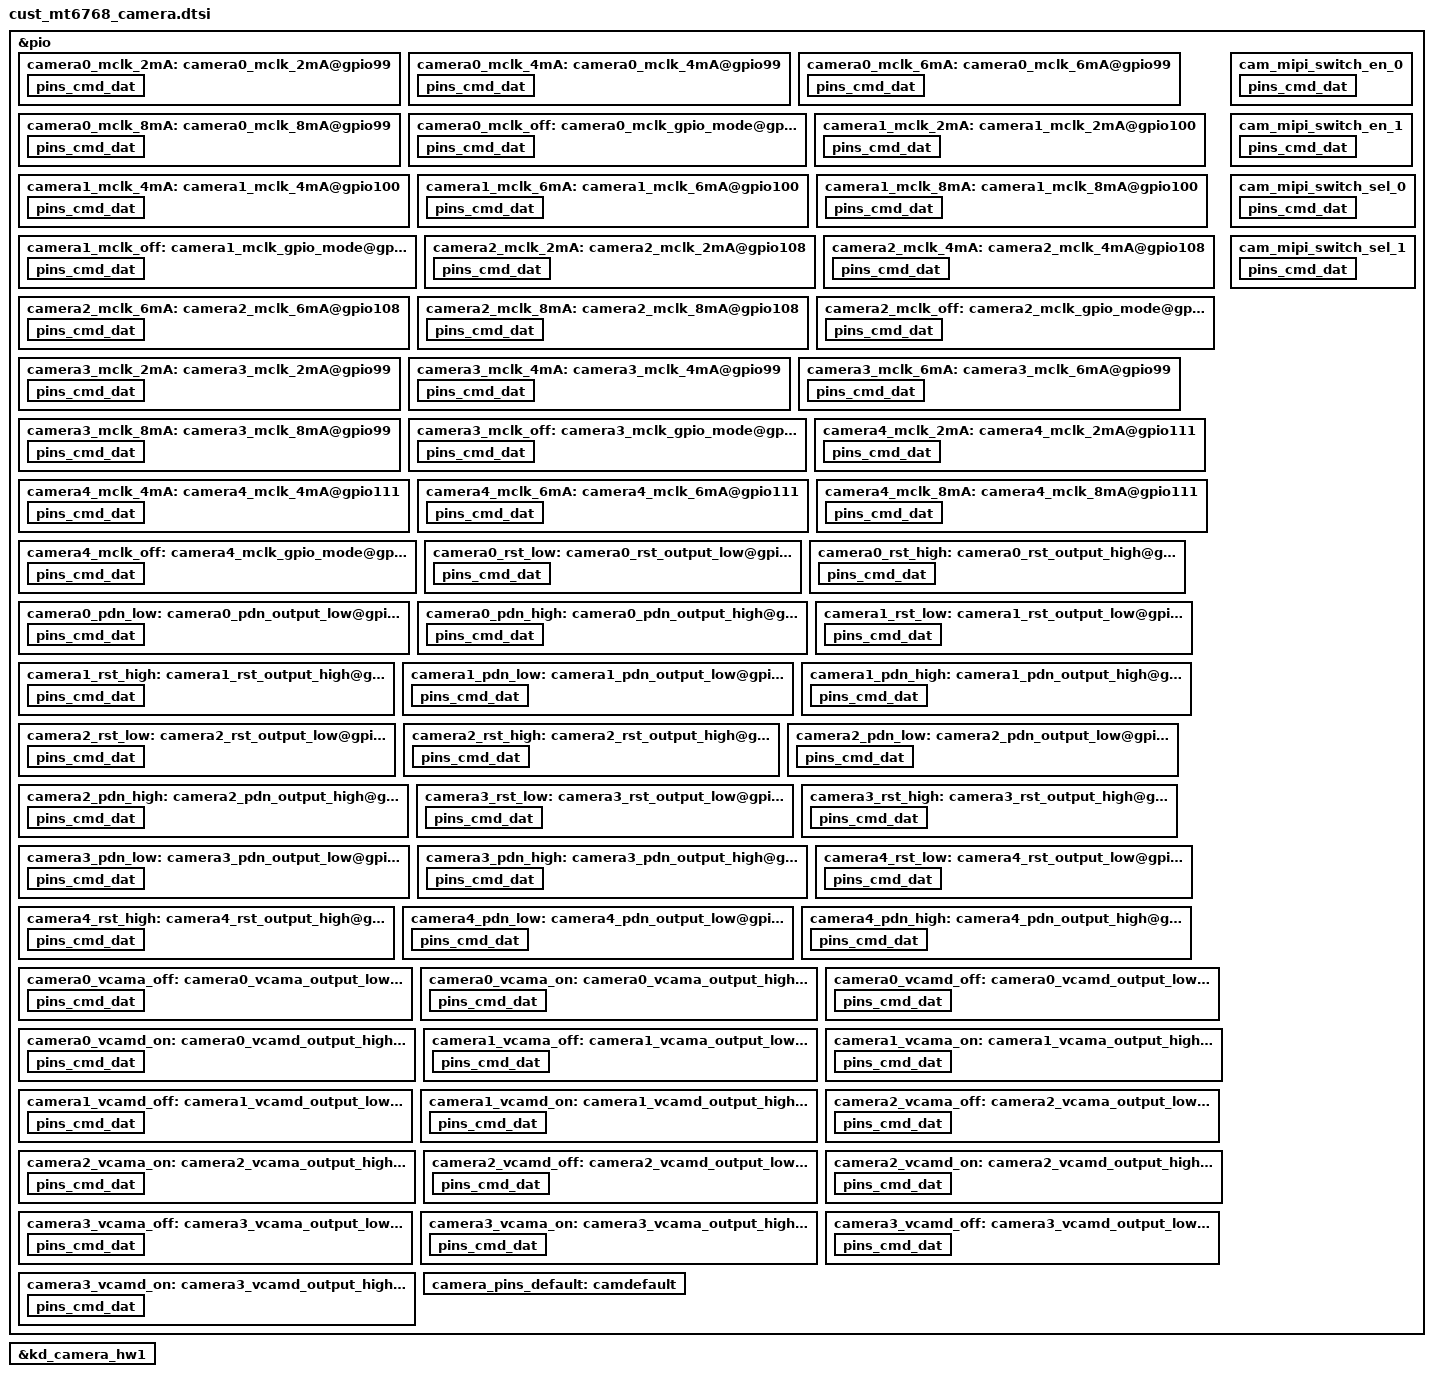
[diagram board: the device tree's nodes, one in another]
/*
 * Copyright (c) 2019 MediaTek Inc.
 *
 * This program is free software; you can redistribute it and/or modify
 * it under the terms of the GNU General Public License version 2 as
 * published by the Free Software Foundation.
 *
 * This program is distributed in the hope that it will be useful,
 * but WITHOUT ANY WARRANTY; without even the implied warranty of
 * MERCHANTABILITY or FITNESS FOR A PARTICULAR PURPOSE.  See the
 * GNU General Public License for more details.
 */
/* CAMERA GPIO standardization */
/*prize add by zhuzhengjiang for 6601 camera 20200902 start*/
&pio {
	camera0_mclk_2mA: camera0_mclk_2mA@gpio99 {
		pins_cmd_dat {
			pinmux = <PINMUX_GPIO99__FUNC_CMMCLK0>;
			drive-strength = <MTK_DRIVE_2mA>;
		};
	};
	camera0_mclk_4mA: camera0_mclk_4mA@gpio99 {
		pins_cmd_dat {
			pinmux = <PINMUX_GPIO99__FUNC_CMMCLK0>;
			drive-strength = <MTK_DRIVE_4mA>;
		};
	};
	camera0_mclk_6mA: camera0_mclk_6mA@gpio99 {
		pins_cmd_dat {
			pinmux = <PINMUX_GPIO99__FUNC_CMMCLK0>;
			drive-strength = <MTK_DRIVE_6mA>;
		};
	};
	camera0_mclk_8mA: camera0_mclk_8mA@gpio99 {
		pins_cmd_dat {
			pinmux = <PINMUX_GPIO99__FUNC_CMMCLK0>;
			drive-strength = <7>;
		};
	};
	camera0_mclk_off: camera0_mclk_gpio_mode@gpio99 {
		pins_cmd_dat {
			pinmux = <PINMUX_GPIO99__FUNC_GPIO99>;
			drive-strength = <MTK_DRIVE_4mA>;
		};
	};
	camera1_mclk_2mA: camera1_mclk_2mA@gpio100 {
		pins_cmd_dat {
			pinmux = <PINMUX_GPIO100__FUNC_CMMCLK1>;
			drive-strength = <MTK_DRIVE_2mA>;
		};
	};
	camera1_mclk_4mA: camera1_mclk_4mA@gpio100 {
		pins_cmd_dat {
			pinmux = <PINMUX_GPIO100__FUNC_CMMCLK1>;
			drive-strength = <MTK_DRIVE_4mA>;
		};
	};
	camera1_mclk_6mA: camera1_mclk_6mA@gpio100 {
		pins_cmd_dat {
			pinmux = <PINMUX_GPIO100__FUNC_CMMCLK1>;
			drive-strength = <MTK_DRIVE_6mA>;
		};
	};
	camera1_mclk_8mA: camera1_mclk_8mA@gpio100 {
		pins_cmd_dat {
			pinmux = <PINMUX_GPIO100__FUNC_CMMCLK1>;
			drive-strength = <7>;
		};
	};
	camera1_mclk_off: camera1_mclk_gpio_mode@gpio100 {
		pins_cmd_dat {
			pinmux = <PINMUX_GPIO100__FUNC_GPIO100>;
			drive-strength = <MTK_DRIVE_4mA>;
		};
	};
	camera2_mclk_2mA: camera2_mclk_2mA@gpio108 {
		pins_cmd_dat {
			pinmux = <PINMUX_GPIO108__FUNC_CMMCLK2>;
			drive-strength = <MTK_DRIVE_2mA>;
		};
	};
	camera2_mclk_4mA: camera2_mclk_4mA@gpio108 {
		pins_cmd_dat {
			pinmux = <PINMUX_GPIO108__FUNC_CMMCLK2>;
			drive-strength = <MTK_DRIVE_4mA>;
		};
	};
	camera2_mclk_6mA: camera2_mclk_6mA@gpio108 {
		pins_cmd_dat {
			pinmux = <PINMUX_GPIO108__FUNC_CMMCLK2>;
			drive-strength = <MTK_DRIVE_6mA>;
		};
	};
	camera2_mclk_8mA: camera2_mclk_8mA@gpio108 {
		pins_cmd_dat {
			pinmux = <PINMUX_GPIO108__FUNC_CMMCLK2>;
			drive-strength = <7>;
		};
	};
	camera2_mclk_off: camera2_mclk_gpio_mode@gpio108 {
		pins_cmd_dat {
			pinmux = <PINMUX_GPIO108__FUNC_GPIO108>;
			drive-strength = <MTK_DRIVE_4mA>;
		};
	};
	//prize add by zhuzhengjiang for mclk start
	camera3_mclk_2mA: camera3_mclk_2mA@gpio99 {
		pins_cmd_dat {
			pinmux = <PINMUX_GPIO99__FUNC_CMMCLK0>;
			drive-strength = <MTK_DRIVE_2mA>;
		};
	};
	camera3_mclk_4mA: camera3_mclk_4mA@gpio99 {
		pins_cmd_dat {
			pinmux = <PINMUX_GPIO99__FUNC_CMMCLK0>;
			drive-strength = <MTK_DRIVE_4mA>;
		};
	};
	camera3_mclk_6mA: camera3_mclk_6mA@gpio99 {
		pins_cmd_dat {
			pinmux = <PINMUX_GPIO99__FUNC_CMMCLK0>;
			drive-strength = <MTK_DRIVE_6mA>;
		};
	};
	camera3_mclk_8mA: camera3_mclk_8mA@gpio99 {
		pins_cmd_dat {
			pinmux = <PINMUX_GPIO99__FUNC_CMMCLK0>;
			drive-strength = <7>;
		};
	};
	camera3_mclk_off: camera3_mclk_gpio_mode@gpio99 {
		pins_cmd_dat {
			pinmux = <PINMUX_GPIO99__FUNC_GPIO99>;
			drive-strength = <MTK_DRIVE_4mA>;
		};
	};
	
	camera4_mclk_2mA: camera4_mclk_2mA@gpio111 {
		pins_cmd_dat {
			pinmux = <PINMUX_GPIO111__FUNC_CMMCLK3>;
			drive-strength = <MTK_DRIVE_2mA>;
		};
	};
	camera4_mclk_4mA: camera4_mclk_4mA@gpio111 {
		pins_cmd_dat {
			pinmux = <PINMUX_GPIO111__FUNC_CMMCLK3>;
			drive-strength = <MTK_DRIVE_4mA>;
		};
	};
	camera4_mclk_6mA: camera4_mclk_6mA@gpio111 {
		pins_cmd_dat {
			pinmux = <PINMUX_GPIO111__FUNC_CMMCLK3>;
			drive-strength = <MTK_DRIVE_6mA>;
		};
	};
	camera4_mclk_8mA: camera4_mclk_8mA@gpio111 {
		pins_cmd_dat {
			pinmux = <PINMUX_GPIO111__FUNC_CMMCLK3>;
			drive-strength = <7>;
		};
	};
	camera4_mclk_off: camera4_mclk_gpio_mode@gpio111 {
		pins_cmd_dat {
			pinmux = <PINMUX_GPIO111__FUNC_GPIO111>;
			drive-strength = <MTK_DRIVE_4mA>;
		};
	};
	//prize add by zhuzhengjiang for mclk end
	camera0_rst_low: camera0_rst_output_low@gpio109 {
		pins_cmd_dat {
			pinmux = <PINMUX_GPIO109__FUNC_GPIO109>;
			output-low;
		};
	};
	camera0_rst_high: camera0_rst_output_high@gpio109 {
		pins_cmd_dat {
			pinmux = <PINMUX_GPIO109__FUNC_GPIO109>;
			output-high;
		};
	};
	camera0_pdn_low: camera0_pdn_output_low@gpio107 {
		pins_cmd_dat {
			pinmux = <PINMUX_GPIO107__FUNC_GPIO107>;
			output-low;
		};
	};
	camera0_pdn_high: camera0_pdn_output_high@gpio107 {
		pins_cmd_dat {
			pinmux = <PINMUX_GPIO107__FUNC_GPIO107>;
			output-high;
		};
	};
	camera1_rst_low: camera1_rst_output_low@gpio102 {
		pins_cmd_dat {
			pinmux = <PINMUX_GPIO102__FUNC_GPIO102>;
			output-low;
		};
	};
	camera1_rst_high: camera1_rst_output_high@gpio102 {
		pins_cmd_dat {
			pinmux = <PINMUX_GPIO102__FUNC_GPIO102>;
			output-high;
		};
	};
	camera1_pdn_low: camera1_pdn_output_low@gpio98 {
		pins_cmd_dat {
			pinmux = <PINMUX_GPIO98__FUNC_GPIO98>;
			slew-rate = <1>;
			output-low;
		};
	};
	camera1_pdn_high: camera1_pdn_output_high@gpio98 {
		pins_cmd_dat {
			pinmux = <PINMUX_GPIO98__FUNC_GPIO98>;
			output-high;
		};
	};
	camera2_rst_low: camera2_rst_output_low@gpio101 {
		pins_cmd_dat {
			pinmux = <PINMUX_GPIO101__FUNC_GPIO101>;
			output-low;
		};
	};
	camera2_rst_high: camera2_rst_output_high@gpio101 {
		pins_cmd_dat {
			pinmux = <PINMUX_GPIO101__FUNC_GPIO101>;
			output-high;
		};
	};
	camera2_pdn_low: camera2_pdn_output_low@gpio97 {
		pins_cmd_dat {
			pinmux = <PINMUX_GPIO97__FUNC_GPIO97>;
			output-low;
		};
	};
	camera2_pdn_high: camera2_pdn_output_high@gpio97 {
		pins_cmd_dat {
			pinmux = <PINMUX_GPIO97__FUNC_GPIO97>;
			output-high;
		};
	};
	//prize add by zhuzhengjiang for cam3/cam4 rst/pdn start
	camera3_rst_low: camera3_rst_output_low@gpio16 {
		pins_cmd_dat {
			pinmux = <PINMUX_GPIO16__FUNC_GPIO16>;
			output-low;
		};
	};
	camera3_rst_high: camera3_rst_output_high@gpio16 {
		pins_cmd_dat {
			pinmux = <PINMUX_GPIO16__FUNC_GPIO16>;
			output-high;
		};
	};
	camera3_pdn_low: camera3_pdn_output_low@gpio14 {
		pins_cmd_dat {
			pinmux = <PINMUX_GPIO14__FUNC_GPIO14>;
			output-low;
		};
	};
	camera3_pdn_high: camera3_pdn_output_high@gpio14 {
		pins_cmd_dat {
			pinmux = <PINMUX_GPIO14__FUNC_GPIO14>;
			output-high;
		};
	};
	
	camera4_rst_low: camera4_rst_output_low@gpio92 {
		pins_cmd_dat {
			pinmux = <PINMUX_GPIO92__FUNC_GPIO92>;
			output-low;
		};
	};
	camera4_rst_high: camera4_rst_output_high@gpio92 {
		pins_cmd_dat {
			pinmux = <PINMUX_GPIO92__FUNC_GPIO92>;
			output-high;
		};
	};
	camera4_pdn_low: camera4_pdn_output_low@gpio110 {
		pins_cmd_dat {
			pinmux = <PINMUX_GPIO110__FUNC_GPIO110>;
			output-low;
		};
	};
	camera4_pdn_high: camera4_pdn_output_high@gpio110 {
		pins_cmd_dat {
			pinmux = <PINMUX_GPIO110__FUNC_GPIO110>;
			output-high;
		};
	};
	//prize add by zhuzhengjiang for cam3/cam4 rst/pdn end
    /* prize liaoxingen add camera dts 20200901 start  */
	camera0_vcama_off: camera0_vcama_output_low@gpio79 {
		pins_cmd_dat {
			pinmux = <PINMUX_GPIO79__FUNC_GPIO79>;
			output-low;
		};
	};
	camera0_vcama_on: camera0_vcama_output_high@gpio79 {
		pins_cmd_dat {
			pinmux = <PINMUX_GPIO79__FUNC_GPIO79>;
			output-high;
		};
	};
    /* prize liaoxingen add camera dts 20200901 end  */

	camera0_vcamd_off: camera0_vcamd_output_low@gpio80 {
		pins_cmd_dat {
			pinmux = <PINMUX_GPIO80__FUNC_GPIO80>;
			output-low;
		};
	};
	camera0_vcamd_on: camera0_vcamd_output_high@gpio80 {
		pins_cmd_dat {
			pinmux = <PINMUX_GPIO80__FUNC_GPIO80>;
			output-high;
		};
	};
    /* prize liaoxingen add camera dts 20200901 start  */
	camera1_vcama_off: camera1_vcama_output_low@gpio54 {
		pins_cmd_dat {
			pinmux = <PINMUX_GPIO54__FUNC_GPIO54>;
			output-low;
		};
	};
	camera1_vcama_on: camera1_vcama_output_high@gpio54 {
		pins_cmd_dat {
			pinmux = <PINMUX_GPIO54__FUNC_GPIO54>;
			output-high;
		};
	};
    /* prize liaoxingen add camera dts 20200901 end  */
	camera1_vcamd_off: camera1_vcamd_output_low@gpio31 {
		pins_cmd_dat {
			pinmux = <PINMUX_GPIO31__FUNC_GPIO31>;
			output-low;
		};
	};
	camera1_vcamd_on: camera1_vcamd_output_high@gpio31 {
		pins_cmd_dat {
			pinmux = <PINMUX_GPIO31__FUNC_GPIO31>;
			output-high;
		};
	};
	camera2_vcama_off: camera2_vcama_output_low@gpio150 {
		pins_cmd_dat {
			pinmux = <PINMUX_GPIO150__FUNC_GPIO150>;
			output-low;
		};
	};
	camera2_vcama_on: camera2_vcama_output_high@gpio150 {
		pins_cmd_dat {
			pinmux = <PINMUX_GPIO150__FUNC_GPIO150>;
			output-high;
		};
	};
	camera2_vcamd_off: camera2_vcamd_output_low@gpio160 {
		pins_cmd_dat {
			pinmux = <PINMUX_GPIO160__FUNC_GPIO160>;
			output-low;
		};
	};
	camera2_vcamd_on: camera2_vcamd_output_high@gpio160 {
		pins_cmd_dat {
			pinmux = <PINMUX_GPIO160__FUNC_GPIO160>;
			output-high;
		};
	};
	camera3_vcama_off: camera3_vcama_output_low@gpio24 {
		pins_cmd_dat {
			pinmux = <PINMUX_GPIO24__FUNC_GPIO24>;
			output-low;
		};
	};
	camera3_vcama_on: camera3_vcama_output_high@gpio24 {
		pins_cmd_dat {
			pinmux = <PINMUX_GPIO24__FUNC_GPIO24>;
			output-high;
		};
	};
	camera3_vcamd_off: camera3_vcamd_output_low@gpio21 {
		pins_cmd_dat {
			pinmux = <PINMUX_GPIO21__FUNC_GPIO21>;
			output-low;
		};
	};
	camera3_vcamd_on: camera3_vcamd_output_high@gpio21 {
		pins_cmd_dat {
			pinmux = <PINMUX_GPIO21__FUNC_GPIO21>;
			output-high;
		};
	};

	cam_mipi_switch_en_0: cam_mipi_switch_en_0 {
		pins_cmd_dat {
			pinmux = <PINMUX_GPIO13__FUNC_GPIO13>;
			slew-rate = <1>;
			output-low;
		};
	};
	cam_mipi_switch_en_1: cam_mipi_switch_en_1 {
		pins_cmd_dat {
			pinmux = <PINMUX_GPIO13__FUNC_GPIO13>;
			slew-rate = <1>;
			output-high;
		};
	};
	cam_mipi_switch_sel_0: cam_mipi_switch_sel_0 {
		pins_cmd_dat {
			pinmux = <PINMUX_GPIO15__FUNC_GPIO15>;
			slew-rate = <1>;
			output-low;
		};
	};
	cam_mipi_switch_sel_1: cam_mipi_switch_sel_1 {
		pins_cmd_dat {
			pinmux = <PINMUX_GPIO15__FUNC_GPIO15>;
			slew-rate = <1>;
			output-high;
		};
	};

	camera_pins_default: camdefault {
	};

};

&kd_camera_hw1 {
	pinctrl-names = "default",
			"cam0_rst0", "cam0_rst1",
			"cam0_pnd0", "cam0_pnd1",
			"cam1_rst0", "cam1_rst1",
			"cam1_pnd0", "cam1_pnd1",
			"cam2_rst0", "cam2_rst1",
			"cam2_pnd0", "cam2_pnd1",
			"cam0_vcamd_on",
			"cam0_vcamd_off",
			"cam1_vcamd_on",
			"cam1_vcamd_off",
			"cam0_vcama_on",
			"cam0_vcama_off",
			"cam1_vcama_on",
			"cam1_vcama_off",
			"cam0_mclk_off",
			"cam0_mclk_2mA", "cam0_mclk_4mA",
			"cam0_mclk_6mA", "cam0_mclk_8mA",
			"cam1_mclk_off",
			"cam1_mclk_2mA", "cam1_mclk_4mA",
			"cam1_mclk_6mA", "cam1_mclk_8mA",
			"cam2_mclk_off",
			"cam2_mclk_2mA", "cam2_mclk_4mA",
			"cam2_mclk_6mA", "cam2_mclk_8mA",

			"cam3_rst0", "cam3_rst1",
			"cam3_pnd0", "cam3_pnd1",
			"cam3_mclk_off",
			"cam3_mclk_2mA", "cam3_mclk_4mA",
			"cam3_mclk_6mA", "cam3_mclk_8mA",

			"cam4_rst0", "cam4_rst1",
			"cam4_pnd0", "cam4_pnd1",
			"cam4_mclk_off",
			"cam4_mclk_2mA", "cam4_mclk_4mA",
			"cam4_mclk_6mA", "cam4_mclk_8mA",

			"cam_mipi_switch_en_0", "cam_mipi_switch_en_1",
			"cam_mipi_switch_sel_0", "cam_mipi_switch_sel_1";

	pinctrl-0 = <&camera_pins_default>;
	pinctrl-1 = <&camera0_rst_low>;
	pinctrl-2 = <&camera0_rst_high>;
	pinctrl-3 = <&camera0_pdn_low>;
	pinctrl-4 = <&camera0_pdn_high>;
	pinctrl-5 = <&camera1_rst_low>;
	pinctrl-6 = <&camera1_rst_high>;
	pinctrl-7 = <&camera1_pdn_low>;
	pinctrl-8 = <&camera1_pdn_high>;
	pinctrl-9 = <&camera2_rst_low>;
	pinctrl-10 = <&camera2_rst_high>;
	pinctrl-11 = <&camera2_pdn_low>;
	pinctrl-12 = <&camera2_pdn_high>;
	pinctrl-13 = <&camera0_vcamd_on>;
	pinctrl-14 = <&camera0_vcamd_off>;
	pinctrl-15 = <&camera1_vcamd_on>;
	pinctrl-16 = <&camera1_vcamd_off>;
	pinctrl-17 = <&camera0_vcama_on>;
	pinctrl-18 = <&camera0_vcama_off>;
	pinctrl-19 = <&camera1_vcama_on>;
	pinctrl-20 = <&camera1_vcama_off>;
	pinctrl-21 = <&camera0_mclk_off>;
	pinctrl-22 = <&camera0_mclk_2mA>;
	pinctrl-23 = <&camera0_mclk_4mA>;
	pinctrl-24 = <&camera0_mclk_6mA>;
	pinctrl-25 = <&camera0_mclk_8mA>;
	pinctrl-26 = <&camera1_mclk_off>;
	pinctrl-27 = <&camera1_mclk_2mA>;
	pinctrl-28 = <&camera1_mclk_4mA>;
	pinctrl-29 = <&camera1_mclk_6mA>;
	pinctrl-30 = <&camera1_mclk_8mA>;
	pinctrl-31 = <&camera2_mclk_off>;
	pinctrl-32 = <&camera2_mclk_2mA>;
	pinctrl-33 = <&camera2_mclk_4mA>;
	pinctrl-34 = <&camera2_mclk_6mA>;
	pinctrl-35 = <&camera2_mclk_8mA>;

	/* camera3 */
	pinctrl-36 = <&camera3_rst_low>;
	pinctrl-37 = <&camera3_rst_high>;
	pinctrl-38 = <&camera3_pdn_low>;
	pinctrl-39 = <&camera3_pdn_high>;
	pinctrl-40 = <&camera3_mclk_off>;
	pinctrl-41 = <&camera3_mclk_2mA>;
	pinctrl-42 = <&camera3_mclk_4mA>;
	pinctrl-43 = <&camera3_mclk_6mA>;
	pinctrl-44 = <&camera3_mclk_8mA>;
	
	pinctrl-45 = <&camera4_rst_low>;
	pinctrl-46 = <&camera4_rst_high>;
	pinctrl-47 = <&camera4_pdn_low>;
	pinctrl-48 = <&camera4_pdn_high>;	
	pinctrl-49 = <&camera4_mclk_off>;
	pinctrl-50 = <&camera4_mclk_2mA>;
	pinctrl-51 = <&camera4_mclk_4mA>;
	pinctrl-52 = <&camera4_mclk_6mA>;
	pinctrl-53 = <&camera4_mclk_8mA>;
	/* mipi switch */
	pinctrl-54 = <&cam_mipi_switch_en_0>;
	pinctrl-55 = <&cam_mipi_switch_en_1>;
	pinctrl-56 = <&cam_mipi_switch_sel_0>;
	pinctrl-57 = <&cam_mipi_switch_sel_1>;

	cam2_vcama-supply = <&mt_pmic_vcama1_ldo_reg>;
	cam3_vcama-supply = <&mt_pmic_vcama1_ldo_reg>;
	cam4_vcama-supply = <&mt_pmic_vcama1_ldo_reg>;
	cam1_vcamd-supply = <&mt_pmic_vcamd_ldo_reg>;
	cam3_vcamd-supply = <&mt_pmic_vcamd_ldo_reg>;

	cam0_vcamio-supply = <&mt_pmic_vcamio_ldo_reg>;
	cam1_vcamio-supply = <&mt_pmic_vcamio_ldo_reg>;
	cam2_vcamio-supply = <&mt_pmic_vcamio_ldo_reg>;
	cam3_vcamio-supply = <&mt_pmic_vcamio_ldo_reg>;
	cam4_vcamio-supply = <&mt_pmic_vcamio_ldo_reg>;

	status = "okay";

};
/*prize add by zhuzhengjiang for 6601 camera 20200902 end */
/* CAMERA GPIO end */
